# SYSCTRL_PADCONF_CORE register map
Vendor: Texas Instruments
Registers are 32-bit, access per field, reset 0x10F010F unless marked. A register's access mark holds for its fields unless they carry their own. Offsets are as the file gives them; [hi:lo] are bit positions; 'fields as' and 'values as' point back to an identical list.

## SYSCTRL_PADCONF_CORE (part 6 of 10)
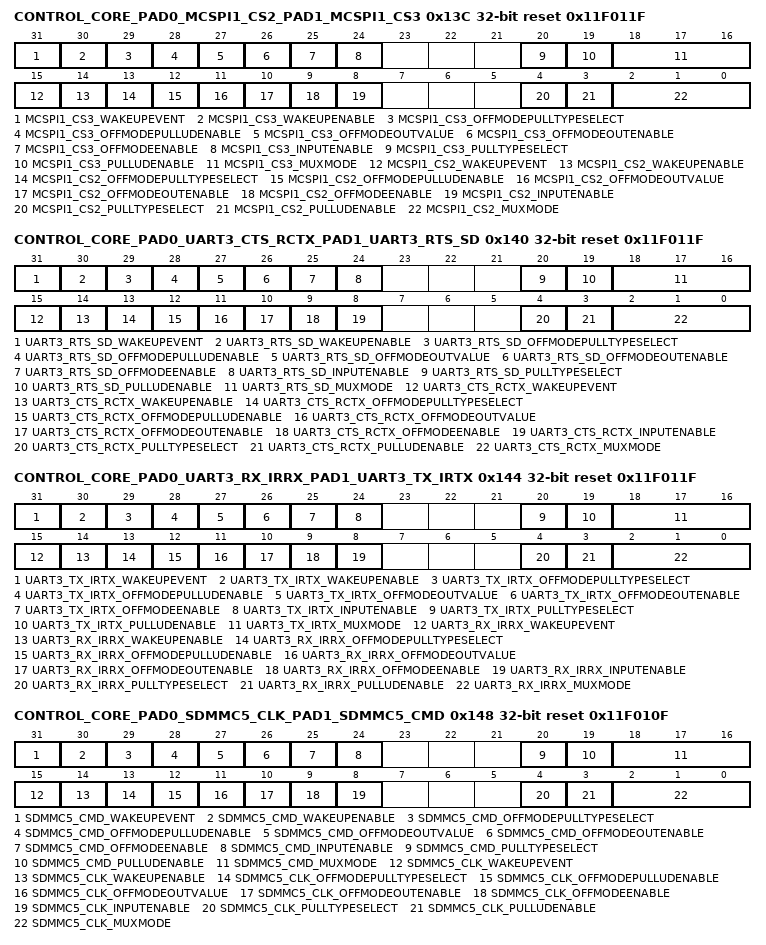
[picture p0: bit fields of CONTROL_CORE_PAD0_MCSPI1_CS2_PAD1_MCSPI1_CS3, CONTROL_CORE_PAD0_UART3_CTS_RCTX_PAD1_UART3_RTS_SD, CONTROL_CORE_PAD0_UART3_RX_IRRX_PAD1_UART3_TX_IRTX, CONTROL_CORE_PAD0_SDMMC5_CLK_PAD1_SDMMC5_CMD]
0x13C CONTROL_CORE_PAD0_MCSPI1_CS2_PAD1_MCSPI1_CS3 reset 0x11F011F — Register control for Pads mcspi1_cs2 and mcspi1_cs3 Access conditions. Read: unrestricted, Write: unrestricted
  [31] MCSPI1_CS3_WAKEUPEVENT ro — Pad_x wake-up event status latched in the IO
    0=MCSPI1_CS3_WAKEUPEVENT_0_r (No wake-up event occurred); 1=MCSPI1_CS3_WAKEUPEVENT_1_r (A wake-up event occurred)
  [30] MCSPI1_CS3_WAKEUPENABLE rw — Input pad wake-up enable (and OFF mode input enable value)
    0=wake-up detection is disabled; 1=wake-up detection is enabled
  [29] MCSPI1_CS3_OFFMODEPULLTYPESELECT rw — OffMode mode pullup/down selection for pad mcspi1_cs3
    0=Offmode pulldown selected; 1=Offmode pullup selected
  [28] MCSPI1_CS3_OFFMODEPULLUDENABLE rw — OffMode mode pullup/down enable for pad mcspi1_cs3
    0=Offmode pullup/down disabled; 1=Offmode pullup/down enabled
  [27] MCSPI1_CS3_OFFMODEOUTVALUE rw — OffMode mode output value for pad mcspi1_cs3
    0=Set value at 0; 1=Set value at 1
  [26] MCSPI1_CS3_OFFMODEOUTENABLE rw — OffMode mode output enable value for pad mcspi1_cs3. This is an active low signal
    0=Output enable; 1=Output disable
  [25] MCSPI1_CS3_OFFMODEENABLE rw — OffMode mode override control for pad mcspi1_cs3
    0=I/O state keeps its previous state when OFF mode is active; 1=I/O state is forced to OFF mode value when OFF mode is active
  [24] MCSPI1_CS3_INPUTENABLE rw — Input enable value for pad mcspi1_cs3
    0=Input buffer of I/O cell is disabled; 1=Input buffer of I/O cell is enabled
  [20] MCSPI1_CS3_PULLTYPESELECT rw — pullup/down selection for pad mcspi1_cs3
    0=pulldown selected; 1=pullup selected
  [19] MCSPI1_CS3_PULLUDENABLE rw — pullup/down enable for pad mcspi1_cs3
    0=pullup/down disabled; 1=pullup/down enabled
  [18:16] MCSPI1_CS3_MUXMODE rw — Functional multiplexing selection for pad mcspi1_cs3
    0=Select mcspi1_cs3; 1=Select uart1_rts; 2=Select slimbus2_data; 3=Select gpio_140; 7=Select safe_mode
  [15] MCSPI1_CS2_WAKEUPEVENT ro — Pad_x wake-up event status latched in the IO
    0=MCSPI1_CS2_WAKEUPEVENT_0_r (No wake-up event occurred); 1=MCSPI1_CS2_WAKEUPEVENT_1_r (A wake-up event occurred)
  [14] MCSPI1_CS2_WAKEUPENABLE rw — Input pad wake-up enable (and OFF mode input enable value)
    values as MCSPI1_CS3_WAKEUPENABLE
  [13] MCSPI1_CS2_OFFMODEPULLTYPESELECT rw — OffMode mode pullup/down selection for pad mcspi1_cs2
    0=Offmode pulldown selected; 1=Offmode pullup selected
  [12] MCSPI1_CS2_OFFMODEPULLUDENABLE rw — OffMode mode pullup/down enable for pad mcspi1_cs2
    values as MCSPI1_CS3_OFFMODEPULLUDENABLE
  [11] MCSPI1_CS2_OFFMODEOUTVALUE rw — OffMode mode output value for pad mcspi1_cs2
    0=Set value at 0; 1=Set value at 1
  [10] MCSPI1_CS2_OFFMODEOUTENABLE rw — OffMode mode output enable value for pad mcspi1_cs2. This is an active low signal
    0=Output enable; 1=Output disable
  [9] MCSPI1_CS2_OFFMODEENABLE rw — OffMode mode override control for pad mcspi1_cs2
    values as MCSPI1_CS3_OFFMODEENABLE
  [8] MCSPI1_CS2_INPUTENABLE rw — Input enable value for pad mcspi1_cs2
    values as MCSPI1_CS3_INPUTENABLE
  [4] MCSPI1_CS2_PULLTYPESELECT rw — pullup/down selection for pad mcspi1_cs2
    0=pulldown selected; 1=pullup selected
  [3] MCSPI1_CS2_PULLUDENABLE rw — pullup/down enable for pad mcspi1_cs2
    0=pullup/down disabled; 1=pullup/down enabled
  [2:0] MCSPI1_CS2_MUXMODE rw — Functional multiplexing selection for pad mcspi1_cs2
    0=Select mcspi1_cs2; 1=Select uart1_cts; 2=Select slimbus2_clock; 3=Select gpio_139; 7=Select safe_mode
0x140 CONTROL_CORE_PAD0_UART3_CTS_RCTX_PAD1_UART3_RTS_SD reset 0x11F011F — Register control for Pads uart3_cts_rctx and uart3_rts_sd Access conditions. Read: unrestricted, Write: unrestricted
  [31] UART3_RTS_SD_WAKEUPEVENT ro — Pad_x wake-up event status latched in the IO
    0=UART3_RTS_SD_WAKEUPEVENT_0_r (No wake-up event occurred); 1=UART3_RTS_SD_WAKEUPEVENT_1_r (A wake-up event occurred)
  [30] UART3_RTS_SD_WAKEUPENABLE rw — Input pad wake-up enable (and OFF mode input enable value)
    values as CONTROL_CORE_PAD0_MCSPI1_CS2_PAD1_MCSPI1_CS3.MCSPI1_CS3_WAKEUPENABLE
  [29] UART3_RTS_SD_OFFMODEPULLTYPESELECT rw — OffMode mode pullup/down selection for pad uart3_rts_sd
    0=Offmode pulldown selected; 1=Offmode pullup selected
  [28] UART3_RTS_SD_OFFMODEPULLUDENABLE rw — OffMode mode pullup/down enable for pad uart3_rts_sd
    values as CONTROL_CORE_PAD0_MCSPI1_CS2_PAD1_MCSPI1_CS3.MCSPI1_CS3_OFFMODEPULLUDENABLE
  [27] UART3_RTS_SD_OFFMODEOUTVALUE rw — OffMode mode output value for pad uart3_rts_sd
    0=Set value at 0; 1=Set value at 1
  [26] UART3_RTS_SD_OFFMODEOUTENABLE rw — OffMode mode output enable value for pad uart3_rts_sd. This is an active low signal
    0=Output enable; 1=Output disable
  [25] UART3_RTS_SD_OFFMODEENABLE rw — OffMode mode override control for pad uart3_rts_sd
    values as CONTROL_CORE_PAD0_MCSPI1_CS2_PAD1_MCSPI1_CS3.MCSPI1_CS3_OFFMODEENABLE
  [24] UART3_RTS_SD_INPUTENABLE rw — Input enable value for pad uart3_rts_sd
    values as CONTROL_CORE_PAD0_MCSPI1_CS2_PAD1_MCSPI1_CS3.MCSPI1_CS3_INPUTENABLE
  [20] UART3_RTS_SD_PULLTYPESELECT rw — pullup/down selection for pad uart3_rts_sd
    0=pulldown selected; 1=pullup selected
  [19] UART3_RTS_SD_PULLUDENABLE rw — pullup/down enable for pad uart3_rts_sd
    0=pullup/down disabled; 1=pullup/down enabled
  [18:16] UART3_RTS_SD_MUXMODE rw — Functional multiplexing selection for pad uart3_rts_sd
    0=Select uart3_rts_sd; 3=Select gpio_142; 7=Select safe_mode
  [15] UART3_CTS_RCTX_WAKEUPEVENT ro — Pad_x wake-up event status latched in the IO
    0=UART3_CTS_RCTX_WAKEUPEVENT_0_r (No wake-up event occurred); 1=UART3_CTS_RCTX_WAKEUPEVENT_1_r (A wake-up event occurred)
  [14] UART3_CTS_RCTX_WAKEUPENABLE rw — Input pad wake-up enable (and OFF mode input enable value)
    values as CONTROL_CORE_PAD0_MCSPI1_CS2_PAD1_MCSPI1_CS3.MCSPI1_CS3_WAKEUPENABLE
  [13] UART3_CTS_RCTX_OFFMODEPULLTYPESELECT rw — OffMode mode pullup/down selection for pad uart3_cts_rctx
    0=Offmode pulldown selected; 1=Offmode pullup selected
  [12] UART3_CTS_RCTX_OFFMODEPULLUDENABLE rw — OffMode mode pullup/down enable for pad uart3_cts_rctx
    values as CONTROL_CORE_PAD0_MCSPI1_CS2_PAD1_MCSPI1_CS3.MCSPI1_CS3_OFFMODEPULLUDENABLE
  [11] UART3_CTS_RCTX_OFFMODEOUTVALUE rw — OffMode mode output value for pad uart3_cts_rctx
    0=Set value at 0; 1=Set value at 1
  [10] UART3_CTS_RCTX_OFFMODEOUTENABLE rw — OffMode mode output enable value for pad uart3_cts_rctx. This is an active low signal
    0=Output enable; 1=Output disable
  [9] UART3_CTS_RCTX_OFFMODEENABLE rw — OffMode mode override control for pad uart3_cts_rctx
    values as CONTROL_CORE_PAD0_MCSPI1_CS2_PAD1_MCSPI1_CS3.MCSPI1_CS3_OFFMODEENABLE
  [8] UART3_CTS_RCTX_INPUTENABLE rw — Input enable value for pad uart3_cts_rctx
    values as CONTROL_CORE_PAD0_MCSPI1_CS2_PAD1_MCSPI1_CS3.MCSPI1_CS3_INPUTENABLE
  [4] UART3_CTS_RCTX_PULLTYPESELECT rw — pullup/down selection for pad uart3_cts_rctx
    0=pulldown selected; 1=pullup selected
  [3] UART3_CTS_RCTX_PULLUDENABLE rw — pullup/down enable for pad uart3_cts_rctx
    0=pullup/down disabled; 1=pullup/down enabled
  [2:0] UART3_CTS_RCTX_MUXMODE rw — Functional multiplexing selection for pad uart3_cts_rctx
    0=Select uart3_cts_rctx; 1=Select uart1_tx; 3=Select gpio_141; 7=Select safe_mode
0x144 CONTROL_CORE_PAD0_UART3_RX_IRRX_PAD1_UART3_TX_IRTX reset 0x11F011F — Register control for Pads uart3_rx_irrx and uart3_tx_irtx Access conditions. Read: unrestricted, Write: unrestricted
  [31] UART3_TX_IRTX_WAKEUPEVENT ro — Pad_x wake-up event status latched in the IO
    0=UART3_TX_IRTX_WAKEUPEVENT_0_r (No wake-up event occurred); 1=UART3_TX_IRTX_WAKEUPEVENT_1_r (A wake-up event occurred)
  [30] UART3_TX_IRTX_WAKEUPENABLE rw — Input pad wake-up enable (and OFF mode input enable value)
    values as CONTROL_CORE_PAD0_MCSPI1_CS2_PAD1_MCSPI1_CS3.MCSPI1_CS3_WAKEUPENABLE
  [29] UART3_TX_IRTX_OFFMODEPULLTYPESELECT rw — OffMode mode pullup/down selection for pad uart3_tx_irtx
    0=Offmode pulldown selected; 1=Offmode pullup selected
  [28] UART3_TX_IRTX_OFFMODEPULLUDENABLE rw — OffMode mode pullup/down enable for pad uart3_tx_irtx
    values as CONTROL_CORE_PAD0_MCSPI1_CS2_PAD1_MCSPI1_CS3.MCSPI1_CS3_OFFMODEPULLUDENABLE
  [27] UART3_TX_IRTX_OFFMODEOUTVALUE rw — OffMode mode output value for pad uart3_tx_irtx
    0=Set value at 0; 1=Set value at 1
  [26] UART3_TX_IRTX_OFFMODEOUTENABLE rw — OffMode mode output enable value for pad uart3_tx_irtx. This is an active low signal
    0=Output enable; 1=Output disable
  [25] UART3_TX_IRTX_OFFMODEENABLE rw — OffMode mode override control for pad uart3_tx_irtx
    values as CONTROL_CORE_PAD0_MCSPI1_CS2_PAD1_MCSPI1_CS3.MCSPI1_CS3_OFFMODEENABLE
  [24] UART3_TX_IRTX_INPUTENABLE rw — Input enable value for pad uart3_tx_irtx
    values as CONTROL_CORE_PAD0_MCSPI1_CS2_PAD1_MCSPI1_CS3.MCSPI1_CS3_INPUTENABLE
  [20] UART3_TX_IRTX_PULLTYPESELECT rw — pullup/down selection for pad uart3_tx_irtx
    0=pulldown selected; 1=pullup selected
  [19] UART3_TX_IRTX_PULLUDENABLE rw — pullup/down enable for pad uart3_tx_irtx
    0=pullup/down disabled; 1=pullup/down enabled
  [18:16] UART3_TX_IRTX_MUXMODE rw — Functional multiplexing selection for pad uart3_tx_irtx
    0=Select uart3_tx_irtx; 1=Select dmtimer9_pwm_evt; 3=Select gpio_144; 7=Select safe_mode
  [15] UART3_RX_IRRX_WAKEUPEVENT ro — Pad_x wake-up event status latched in the IO
    0=UART3_RX_IRRX_WAKEUPEVENT_0_r (No wake-up event occurred); 1=UART3_RX_IRRX_WAKEUPEVENT_1_r (A wake-up event occurred)
  [14] UART3_RX_IRRX_WAKEUPENABLE rw — Input pad wake-up enable (and OFF mode input enable value)
    values as CONTROL_CORE_PAD0_MCSPI1_CS2_PAD1_MCSPI1_CS3.MCSPI1_CS3_WAKEUPENABLE
  [13] UART3_RX_IRRX_OFFMODEPULLTYPESELECT rw — OffMode mode pullup/down selection for pad uart3_rx_irrx
    0=Offmode pulldown selected; 1=Offmode pullup selected
  [12] UART3_RX_IRRX_OFFMODEPULLUDENABLE rw — OffMode mode pullup/down enable for pad uart3_rx_irrx
    values as CONTROL_CORE_PAD0_MCSPI1_CS2_PAD1_MCSPI1_CS3.MCSPI1_CS3_OFFMODEPULLUDENABLE
  [11] UART3_RX_IRRX_OFFMODEOUTVALUE rw — OffMode mode output value for pad uart3_rx_irrx
    0=Set value at 0; 1=Set value at 1
  [10] UART3_RX_IRRX_OFFMODEOUTENABLE rw — OffMode mode output enable value for pad uart3_rx_irrx. This is an active low signal
    0=Output enable; 1=Output disable
  [9] UART3_RX_IRRX_OFFMODEENABLE rw — OffMode mode override control for pad uart3_rx_irrx
    values as CONTROL_CORE_PAD0_MCSPI1_CS2_PAD1_MCSPI1_CS3.MCSPI1_CS3_OFFMODEENABLE
  [8] UART3_RX_IRRX_INPUTENABLE rw — Input enable value for pad uart3_rx_irrx
    values as CONTROL_CORE_PAD0_MCSPI1_CS2_PAD1_MCSPI1_CS3.MCSPI1_CS3_INPUTENABLE
  [4] UART3_RX_IRRX_PULLTYPESELECT rw — pullup/down selection for pad uart3_rx_irrx
    0=pulldown selected; 1=pullup selected
  [3] UART3_RX_IRRX_PULLUDENABLE rw — pullup/down enable for pad uart3_rx_irrx
    0=pullup/down disabled; 1=pullup/down enabled
  [2:0] UART3_RX_IRRX_MUXMODE rw — Functional multiplexing selection for pad uart3_rx_irrx
    0=Select uart3_rx_irrx; 1=Select dmtimer8_pwm_evt; 3=Select gpio_143; 7=Select safe_mode
0x148 CONTROL_CORE_PAD0_SDMMC5_CLK_PAD1_SDMMC5_CMD reset 0x11F010F — Register control for Pads sdmmc5_clk and sdmmc5_cmd Access conditions. Read: unrestricted, Write: unrestricted
  [31] SDMMC5_CMD_WAKEUPEVENT ro — Pad_x wake-up event status latched in the IO
    0=SDMMC5_CMD_WAKEUPEVENT_0_r (No wake-up event occurred); 1=SDMMC5_CMD_WAKEUPEVENT_1_r (A wake-up event occurred)
  [30] SDMMC5_CMD_WAKEUPENABLE rw — Input pad wake-up enable (and OFF mode input enable value)
    values as CONTROL_CORE_PAD0_MCSPI1_CS2_PAD1_MCSPI1_CS3.MCSPI1_CS3_WAKEUPENABLE
  [29] SDMMC5_CMD_OFFMODEPULLTYPESELECT rw — OffMode mode pullup/down selection for pad sdmmc5_cmd
    0=Offmode pulldown selected; 1=Offmode pullup selected
  [28] SDMMC5_CMD_OFFMODEPULLUDENABLE rw — OffMode mode pullup/down enable for pad sdmmc5_cmd
    values as CONTROL_CORE_PAD0_MCSPI1_CS2_PAD1_MCSPI1_CS3.MCSPI1_CS3_OFFMODEPULLUDENABLE
  [27] SDMMC5_CMD_OFFMODEOUTVALUE rw — OffMode mode output value for pad sdmmc5_cmd
    0=Set value at 0; 1=Set value at 1
  [26] SDMMC5_CMD_OFFMODEOUTENABLE rw — OffMode mode output enable value for pad sdmmc5_cmd. This is an active low signal
    0=Output enable; 1=Output disable
  [25] SDMMC5_CMD_OFFMODEENABLE rw — OffMode mode override control for pad sdmmc5_cmd
    values as CONTROL_CORE_PAD0_MCSPI1_CS2_PAD1_MCSPI1_CS3.MCSPI1_CS3_OFFMODEENABLE
  [24] SDMMC5_CMD_INPUTENABLE rw — Input enable value for pad sdmmc5_cmd
    values as CONTROL_CORE_PAD0_MCSPI1_CS2_PAD1_MCSPI1_CS3.MCSPI1_CS3_INPUTENABLE
  [20] SDMMC5_CMD_PULLTYPESELECT rw — pullup/down selection for pad sdmmc5_cmd
    0=pulldown selected; 1=pullup selected
  [19] SDMMC5_CMD_PULLUDENABLE rw — pullup/down enable for pad sdmmc5_cmd
    0=pullup/down disabled; 1=pullup/down enabled
  [18:16] SDMMC5_CMD_MUXMODE rw — Functional multiplexing selection for pad sdmmc5_cmd
    0=Select sdmmc5_cmd; 1=Select mcspi2_simo; 2=Select usbc1_icusb_dm; 3=Select gpio_146; 5=Select sdmmc2_cmd; 7=Select safe_mode
  [15] SDMMC5_CLK_WAKEUPEVENT ro — Pad_x wake-up event status latched in the IO
    0=SDMMC5_CLK_WAKEUPEVENT_0_r (No wake-up event occurred); 1=SDMMC5_CLK_WAKEUPEVENT_1_r (A wake-up event occurred)
  [14] SDMMC5_CLK_WAKEUPENABLE rw — Input pad wake-up enable (and OFF mode input enable value)
    values as CONTROL_CORE_PAD0_MCSPI1_CS2_PAD1_MCSPI1_CS3.MCSPI1_CS3_WAKEUPENABLE
  [13] SDMMC5_CLK_OFFMODEPULLTYPESELECT rw — OffMode mode pullup/down selection for pad sdmmc5_clk
    0=Offmode pulldown selected; 1=Offmode pullup selected
  [12] SDMMC5_CLK_OFFMODEPULLUDENABLE rw — OffMode mode pullup/down enable for pad sdmmc5_clk
    values as CONTROL_CORE_PAD0_MCSPI1_CS2_PAD1_MCSPI1_CS3.MCSPI1_CS3_OFFMODEPULLUDENABLE
  [11] SDMMC5_CLK_OFFMODEOUTVALUE rw — OffMode mode output value for pad sdmmc5_clk
    0=Set value at 0; 1=Set value at 1
  [10] SDMMC5_CLK_OFFMODEOUTENABLE rw — OffMode mode output enable value for pad sdmmc5_clk. This is an active low signal
    0=Output enable; 1=Output disable
  [9] SDMMC5_CLK_OFFMODEENABLE rw — OffMode mode override control for pad sdmmc5_clk
    values as CONTROL_CORE_PAD0_MCSPI1_CS2_PAD1_MCSPI1_CS3.MCSPI1_CS3_OFFMODEENABLE
  [8] SDMMC5_CLK_INPUTENABLE rw — Input enable value for pad sdmmc5_clk
    values as CONTROL_CORE_PAD0_MCSPI1_CS2_PAD1_MCSPI1_CS3.MCSPI1_CS3_INPUTENABLE
  [4] SDMMC5_CLK_PULLTYPESELECT rw — pullup/down selection for pad sdmmc5_clk
    0=pulldown selected; 1=pullup selected
  [3] SDMMC5_CLK_PULLUDENABLE rw — pullup/down enable for pad sdmmc5_clk
    0=pullup/down disabled; 1=pullup/down enabled
  [2:0] SDMMC5_CLK_MUXMODE rw — Functional multiplexing selection for pad sdmmc5_clk
    0=Select sdmmc5_clk; 1=Select mcspi2_clk; 2=Select usbc1_icusb_dp; 3=Select gpio_145; 5=Select sdmmc2_clk; 7=Select safe_mode
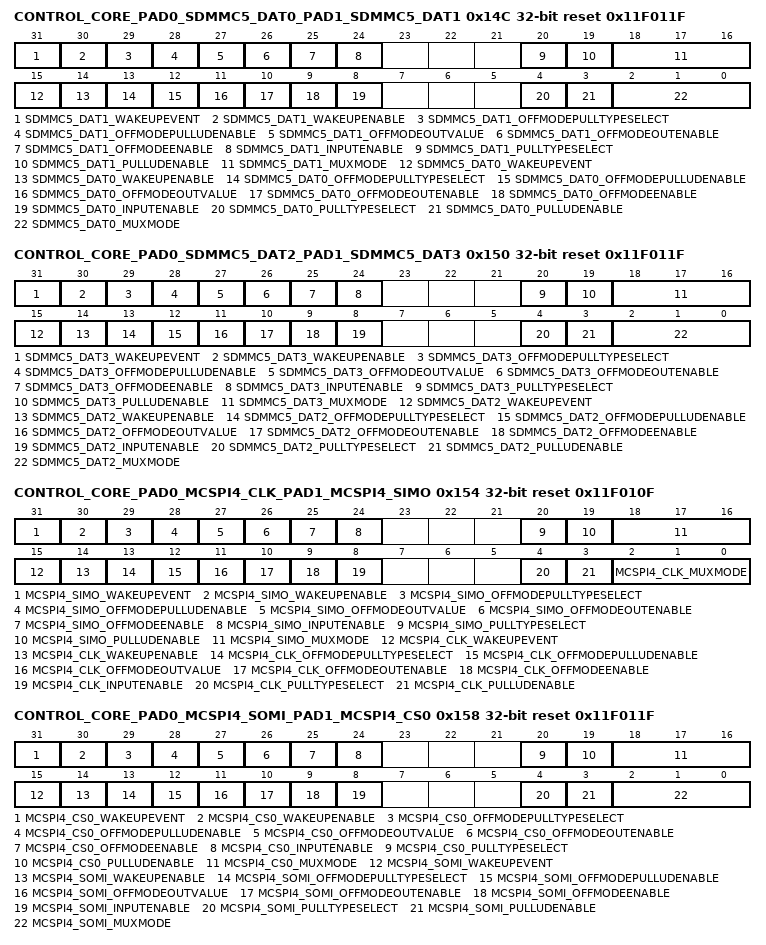
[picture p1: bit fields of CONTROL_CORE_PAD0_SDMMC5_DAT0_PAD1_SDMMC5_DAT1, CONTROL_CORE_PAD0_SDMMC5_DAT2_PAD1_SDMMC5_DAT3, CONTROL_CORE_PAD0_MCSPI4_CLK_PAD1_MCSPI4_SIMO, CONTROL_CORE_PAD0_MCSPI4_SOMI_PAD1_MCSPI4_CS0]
0x14C CONTROL_CORE_PAD0_SDMMC5_DAT0_PAD1_SDMMC5_DAT1 reset 0x11F011F — Register control for Pads sdmmc5_dat0 and sdmmc5_dat1 Access conditions. Read: unrestricted, Write: unrestricted
  [31] SDMMC5_DAT1_WAKEUPEVENT ro — Pad_x wake-up event status latched in the IO
    0=SDMMC5_DAT1_WAKEUPEVENT_0_r (No wake-up event occurred); 1=SDMMC5_DAT1_WAKEUPEVENT_1_r (A wake-up event occurred)
  [30] SDMMC5_DAT1_WAKEUPENABLE rw — Input pad wake-up enable (and OFF mode input enable value)
    values as CONTROL_CORE_PAD0_MCSPI1_CS2_PAD1_MCSPI1_CS3.MCSPI1_CS3_WAKEUPENABLE
  [29] SDMMC5_DAT1_OFFMODEPULLTYPESELECT rw — OffMode mode pullup/down selection for pad sdmmc5_dat1
    0=Offmode pulldown selected; 1=Offmode pullup selected
  [28] SDMMC5_DAT1_OFFMODEPULLUDENABLE rw — OffMode mode pullup/down enable for pad sdmmc5_dat1
    values as CONTROL_CORE_PAD0_MCSPI1_CS2_PAD1_MCSPI1_CS3.MCSPI1_CS3_OFFMODEPULLUDENABLE
  [27] SDMMC5_DAT1_OFFMODEOUTVALUE rw — OffMode mode output value for pad sdmmc5_dat1
    0=Set value at 0; 1=Set value at 1
  [26] SDMMC5_DAT1_OFFMODEOUTENABLE rw — OffMode mode output enable value for pad sdmmc5_dat1. This is an active low signal
    0=Output enable; 1=Output disable
  [25] SDMMC5_DAT1_OFFMODEENABLE rw — OffMode mode override control for pad sdmmc5_dat1
    values as CONTROL_CORE_PAD0_MCSPI1_CS2_PAD1_MCSPI1_CS3.MCSPI1_CS3_OFFMODEENABLE
  [24] SDMMC5_DAT1_INPUTENABLE rw — Input enable value for pad sdmmc5_dat1
    values as CONTROL_CORE_PAD0_MCSPI1_CS2_PAD1_MCSPI1_CS3.MCSPI1_CS3_INPUTENABLE
  [20] SDMMC5_DAT1_PULLTYPESELECT rw — pullup/down selection for pad sdmmc5_dat1
    0=pulldown selected; 1=pullup selected
  [19] SDMMC5_DAT1_PULLUDENABLE rw — pullup/down enable for pad sdmmc5_dat1
    0=pullup/down disabled; 1=pullup/down enabled
  [18:16] SDMMC5_DAT1_MUXMODE rw — Functional multiplexing selection for pad sdmmc5_dat1
    0=Select sdmmc5_dat1; 2=Select usbc1_icusb_txen; 3=Select gpio_148; 5=Select sdmmc2_dat1; 7=Select safe_mode
  [15] SDMMC5_DAT0_WAKEUPEVENT ro — Pad_x wake-up event status latched in the IO
    0=SDMMC5_DAT0_WAKEUPEVENT_0_r (No wake-up event occurred); 1=SDMMC5_DAT0_WAKEUPEVENT_1_r (A wake-up event occurred)
  [14] SDMMC5_DAT0_WAKEUPENABLE rw — Input pad wake-up enable (and OFF mode input enable value)
    values as CONTROL_CORE_PAD0_MCSPI1_CS2_PAD1_MCSPI1_CS3.MCSPI1_CS3_WAKEUPENABLE
  [13] SDMMC5_DAT0_OFFMODEPULLTYPESELECT rw — OffMode mode pullup/down selection for pad sdmmc5_dat0
    0=Offmode pulldown selected; 1=Offmode pullup selected
  [12] SDMMC5_DAT0_OFFMODEPULLUDENABLE rw — OffMode mode pullup/down enable for pad sdmmc5_dat0
    values as CONTROL_CORE_PAD0_MCSPI1_CS2_PAD1_MCSPI1_CS3.MCSPI1_CS3_OFFMODEPULLUDENABLE
  [11] SDMMC5_DAT0_OFFMODEOUTVALUE rw — OffMode mode output value for pad sdmmc5_dat0
    0=Set value at 0; 1=Set value at 1
  [10] SDMMC5_DAT0_OFFMODEOUTENABLE rw — OffMode mode output enable value for pad sdmmc5_dat0. This is an active low signal
    0=Output enable; 1=Output disable
  [9] SDMMC5_DAT0_OFFMODEENABLE rw — OffMode mode override control for pad sdmmc5_dat0
    values as CONTROL_CORE_PAD0_MCSPI1_CS2_PAD1_MCSPI1_CS3.MCSPI1_CS3_OFFMODEENABLE
  [8] SDMMC5_DAT0_INPUTENABLE rw — Input enable value for pad sdmmc5_dat0
    values as CONTROL_CORE_PAD0_MCSPI1_CS2_PAD1_MCSPI1_CS3.MCSPI1_CS3_INPUTENABLE
  [4] SDMMC5_DAT0_PULLTYPESELECT rw — pullup/down selection for pad sdmmc5_dat0
    0=pulldown selected; 1=pullup selected
  [3] SDMMC5_DAT0_PULLUDENABLE rw — pullup/down enable for pad sdmmc5_dat0
    0=pullup/down disabled; 1=pullup/down enabled
  [2:0] SDMMC5_DAT0_MUXMODE rw — Functional multiplexing selection for pad sdmmc5_dat0
    0=Select sdmmc5_dat0; 1=Select mcspi2_somi; 2=Select usbc1_icusb_rcv; 3=Select gpio_147; 5=sdmmc2_dat0; 7=Select safe_mode
0x150 CONTROL_CORE_PAD0_SDMMC5_DAT2_PAD1_SDMMC5_DAT3 reset 0x11F011F — Register control for Pads sdmmc5_dat2 and sdmmc5_dat3 Access conditions. Read: unrestricted, Write: unrestricted
  [31] SDMMC5_DAT3_WAKEUPEVENT ro — Pad_x wake-up event status latched in the IO
    0=SDMMC5_DAT3_WAKEUPEVENT_0_r (No wake-up event occurred); 1=SDMMC5_DAT3_WAKEUPEVENT_1_r (A wake-up event occurred)
  [30] SDMMC5_DAT3_WAKEUPENABLE rw — Input pad wake-up enable (and OFF mode input enable value)
    values as CONTROL_CORE_PAD0_MCSPI1_CS2_PAD1_MCSPI1_CS3.MCSPI1_CS3_WAKEUPENABLE
  [29] SDMMC5_DAT3_OFFMODEPULLTYPESELECT rw — OffMode mode pullup/down selection for pad sdmmc5_dat3
    0=Offmode pulldown selected; 1=Offmode pullup selected
  [28] SDMMC5_DAT3_OFFMODEPULLUDENABLE rw — OffMode mode pullup/down enable for pad sdmmc5_dat3
    values as CONTROL_CORE_PAD0_MCSPI1_CS2_PAD1_MCSPI1_CS3.MCSPI1_CS3_OFFMODEPULLUDENABLE
  [27] SDMMC5_DAT3_OFFMODEOUTVALUE rw — OffMode mode output value for pad sdmmc5_dat3
    0=Set value at 0; 1=Set value at 1
  [26] SDMMC5_DAT3_OFFMODEOUTENABLE rw — OffMode mode output enable value for pad sdmmc5_dat3. This is an active low signal
    0=Output enable; 1=Output disable
  [25] SDMMC5_DAT3_OFFMODEENABLE rw — OffMode mode override control for pad sdmmc5_dat3
    values as CONTROL_CORE_PAD0_MCSPI1_CS2_PAD1_MCSPI1_CS3.MCSPI1_CS3_OFFMODEENABLE
  [24] SDMMC5_DAT3_INPUTENABLE rw — Input enable value for pad sdmmc5_dat3
    values as CONTROL_CORE_PAD0_MCSPI1_CS2_PAD1_MCSPI1_CS3.MCSPI1_CS3_INPUTENABLE
  [20] SDMMC5_DAT3_PULLTYPESELECT rw — pullup/down selection for pad sdmmc5_dat3
    0=pulldown selected; 1=pullup selected
  [19] SDMMC5_DAT3_PULLUDENABLE rw — pullup/down enable for pad sdmmc5_dat3
    0=pullup/down disabled; 1=pullup/down enabled
  [18:16] SDMMC5_DAT3_MUXMODE rw — Functional multiplexing selection for pad sdmmc5_dat3
    0=Select sdmmc5_dat3; 1=Select mcspi2_cs0; 3=Select gpio_150; 5=Select sdmmc2_dat3; 7=Select safe_mode
  [15] SDMMC5_DAT2_WAKEUPEVENT ro — Pad_x wake-up event status latched in the IO
    0=SDMMC5_DAT2_WAKEUPEVENT_0_r (No wake-up event occurred); 1=SDMMC5_DAT2_WAKEUPEVENT_1_r (A wake-up event occurred)
  [14] SDMMC5_DAT2_WAKEUPENABLE rw — Input pad wake-up enable (and OFF mode input enable value)
    values as CONTROL_CORE_PAD0_MCSPI1_CS2_PAD1_MCSPI1_CS3.MCSPI1_CS3_WAKEUPENABLE
  [13] SDMMC5_DAT2_OFFMODEPULLTYPESELECT rw — OffMode mode pullup/down selection for pad sdmmc5_dat2
    0=Offmode pulldown selected; 1=Offmode pullup selected
  [12] SDMMC5_DAT2_OFFMODEPULLUDENABLE rw — OffMode mode pullup/down enable for pad sdmmc5_dat2
    values as CONTROL_CORE_PAD0_MCSPI1_CS2_PAD1_MCSPI1_CS3.MCSPI1_CS3_OFFMODEPULLUDENABLE
  [11] SDMMC5_DAT2_OFFMODEOUTVALUE rw — OffMode mode output value for pad sdmmc5_dat2
    0=Set value at 0; 1=Set value at 1
  [10] SDMMC5_DAT2_OFFMODEOUTENABLE rw — OffMode mode output enable value for pad sdmmc5_dat2. This is an active low signal
    0=Output enable; 1=Output disable
  [9] SDMMC5_DAT2_OFFMODEENABLE rw — OffMode mode override control for pad sdmmc5_dat2
    values as CONTROL_CORE_PAD0_MCSPI1_CS2_PAD1_MCSPI1_CS3.MCSPI1_CS3_OFFMODEENABLE
  [8] SDMMC5_DAT2_INPUTENABLE rw — Input enable value for pad sdmmc5_dat2
    values as CONTROL_CORE_PAD0_MCSPI1_CS2_PAD1_MCSPI1_CS3.MCSPI1_CS3_INPUTENABLE
  [4] SDMMC5_DAT2_PULLTYPESELECT rw — pullup/down selection for pad sdmmc5_dat2
    0=pulldown selected; 1=pullup selected
  [3] SDMMC5_DAT2_PULLUDENABLE rw — pullup/down enable for pad sdmmc5_dat2
    0=pullup/down disabled; 1=pullup/down enabled
  [2:0] SDMMC5_DAT2_MUXMODE rw — Functional multiplexing selection for pad sdmmc5_dat2
    0=Select sdmmc5_dat2; 1=Select mcspi2_cs1; 3=Select gpio_149; 5=Select sdmmc2_dat2; 7=Select safe_mode
0x154 CONTROL_CORE_PAD0_MCSPI4_CLK_PAD1_MCSPI4_SIMO reset 0x11F010F — Register control for Pads mcspi4_clk and mcspi4_simo Access conditions. Read: unrestricted, Write: unrestricted
  [31] MCSPI4_SIMO_WAKEUPEVENT ro — Pad_x wake-up event status latched in the IO
    0=MCSPI4_SIMO_WAKEUPEVENT_0_r (No wake-up event occurred); 1=MCSPI4_SIMO_WAKEUPEVENT_1_r (A wake-up event occurred)
  [30] MCSPI4_SIMO_WAKEUPENABLE rw — Input pad wake-up enable (and OFF mode input enable value)
    values as CONTROL_CORE_PAD0_MCSPI1_CS2_PAD1_MCSPI1_CS3.MCSPI1_CS3_WAKEUPENABLE
  [29] MCSPI4_SIMO_OFFMODEPULLTYPESELECT rw — OffMode mode pullup/down selection for pad mcspi4_simo
    0=Offmode pulldown selected; 1=Offmode pullup selected
  [28] MCSPI4_SIMO_OFFMODEPULLUDENABLE rw — OffMode mode pullup/down enable for pad mcspi4_simo
    values as CONTROL_CORE_PAD0_MCSPI1_CS2_PAD1_MCSPI1_CS3.MCSPI1_CS3_OFFMODEPULLUDENABLE
  [27] MCSPI4_SIMO_OFFMODEOUTVALUE rw — OffMode mode output value for pad mcspi4_simo
    0=Set value at 0; 1=Set value at 1
  [26] MCSPI4_SIMO_OFFMODEOUTENABLE rw — OffMode mode output enable value for pad mcspi4_simo. This is an active low signal
    0=Output enable; 1=Output disable
  [25] MCSPI4_SIMO_OFFMODEENABLE rw — OffMode mode override control for pad mcspi4_simo
    values as CONTROL_CORE_PAD0_MCSPI1_CS2_PAD1_MCSPI1_CS3.MCSPI1_CS3_OFFMODEENABLE
  [24] MCSPI4_SIMO_INPUTENABLE rw — Input enable value for pad mcspi4_simo
    values as CONTROL_CORE_PAD0_MCSPI1_CS2_PAD1_MCSPI1_CS3.MCSPI1_CS3_INPUTENABLE
  [20] MCSPI4_SIMO_PULLTYPESELECT rw — pullup/down selection for pad mcspi4_simo
    0=pulldown selected; 1=pullup selected
  [19] MCSPI4_SIMO_PULLUDENABLE rw — pullup/down enable for pad mcspi4_simo
    0=pullup/down disabled; 1=pullup/down enabled
  [18:16] MCSPI4_SIMO_MUXMODE rw — Functional multiplexing selection for pad mcspi4_simo
    0=Select mcspi4_simo; 1=Select sdmmc4_cmd; 2=Select kpd_col7; 3=Select gpio_152; 7=Select safe_mode
  [15] MCSPI4_CLK_WAKEUPEVENT ro — Pad_x wake-up event status latched in the IO
    0=MCSPI4_CLK_WAKEUPEVENT_0_r (No wake-up event occurred); 1=MCSPI4_CLK_WAKEUPEVENT_1_r (A wake-up event occurred)
  [14] MCSPI4_CLK_WAKEUPENABLE rw — Input pad wake-up enable (and OFF mode input enable value)
    values as CONTROL_CORE_PAD0_MCSPI1_CS2_PAD1_MCSPI1_CS3.MCSPI1_CS3_WAKEUPENABLE
  [13] MCSPI4_CLK_OFFMODEPULLTYPESELECT rw — OffMode mode pullup/down selection for pad mcspi4_clk
    0=Offmode pulldown selected; 1=Offmode pullup selected
  [12] MCSPI4_CLK_OFFMODEPULLUDENABLE rw — OffMode mode pullup/down enable for pad mcspi4_clk
    values as CONTROL_CORE_PAD0_MCSPI1_CS2_PAD1_MCSPI1_CS3.MCSPI1_CS3_OFFMODEPULLUDENABLE
  [11] MCSPI4_CLK_OFFMODEOUTVALUE rw — OffMode mode output value for pad mcspi4_clk
    0=Set value at 0; 1=Set value at 1
  [10] MCSPI4_CLK_OFFMODEOUTENABLE rw — OffMode mode output enable value for pad mcspi4_clk. This is an active low signal
    0=Output enable; 1=Output disable
  [9] MCSPI4_CLK_OFFMODEENABLE rw — OffMode mode override control for pad mcspi4_clk
    values as CONTROL_CORE_PAD0_MCSPI1_CS2_PAD1_MCSPI1_CS3.MCSPI1_CS3_OFFMODEENABLE
  [8] MCSPI4_CLK_INPUTENABLE rw — Input enable value for pad mcspi4_clk
    values as CONTROL_CORE_PAD0_MCSPI1_CS2_PAD1_MCSPI1_CS3.MCSPI1_CS3_INPUTENABLE
  [4] MCSPI4_CLK_PULLTYPESELECT rw — pullup/down selection for pad mcspi4_clk
    0=pulldown selected; 1=pullup selected
  [3] MCSPI4_CLK_PULLUDENABLE rw — pullup/down enable for pad mcspi4_clk
    0=pullup/down disabled; 1=pullup/down enabled
  [2:0] MCSPI4_CLK_MUXMODE rw — Functional multiplexing selection for pad mcspi4_clk
    0=Select mcspi4_clk; 1=Select sdmmc4_clk; 2=Select kpd_col6; 3=Select gpio_151; 7=Select safe_mode
0x158 CONTROL_CORE_PAD0_MCSPI4_SOMI_PAD1_MCSPI4_CS0 reset 0x11F011F — Register control for Pads mcspi4_somi and mcspi4_cs0 Access conditions. Read: unrestricted, Write: unrestricted
  [31] MCSPI4_CS0_WAKEUPEVENT ro — Pad_x wake-up event status latched in the IO
    0=MCSPI4_CS0_WAKEUPEVENT_0_r (No wake-up event occurred); 1=MCSPI4_CS0_WAKEUPEVENT_1_r (A wake-up event occurred)
  [30] MCSPI4_CS0_WAKEUPENABLE rw — Input pad wake-up enable (and OFF mode input enable value)
    values as CONTROL_CORE_PAD0_MCSPI1_CS2_PAD1_MCSPI1_CS3.MCSPI1_CS3_WAKEUPENABLE
  [29] MCSPI4_CS0_OFFMODEPULLTYPESELECT rw — OffMode mode pullup/down selection for pad mcspi4_cs0
    0=Offmode pulldown selected; 1=Offmode pullup selected
  [28] MCSPI4_CS0_OFFMODEPULLUDENABLE rw — OffMode mode pullup/down enable for pad mcspi4_cs0
    values as CONTROL_CORE_PAD0_MCSPI1_CS2_PAD1_MCSPI1_CS3.MCSPI1_CS3_OFFMODEPULLUDENABLE
  [27] MCSPI4_CS0_OFFMODEOUTVALUE rw — OffMode mode output value for pad mcspi4_cs0
    0=Set value at 0; 1=Set value at 1
  [26] MCSPI4_CS0_OFFMODEOUTENABLE rw — OffMode mode output enable value for pad mcspi4_cs0. This is an active low signal
    0=Output enable; 1=Output disable
  [25] MCSPI4_CS0_OFFMODEENABLE rw — OffMode mode override control for pad mcspi4_cs0
    values as CONTROL_CORE_PAD0_MCSPI1_CS2_PAD1_MCSPI1_CS3.MCSPI1_CS3_OFFMODEENABLE
  [24] MCSPI4_CS0_INPUTENABLE rw — Input enable value for pad mcspi4_cs0
    values as CONTROL_CORE_PAD0_MCSPI1_CS2_PAD1_MCSPI1_CS3.MCSPI1_CS3_INPUTENABLE
  [20] MCSPI4_CS0_PULLTYPESELECT rw — pullup/down selection for pad mcspi4_cs0
    0=pulldown selected; 1=pullup selected
  [19] MCSPI4_CS0_PULLUDENABLE rw — pullup/down enable for pad mcspi4_cs0
    0=pullup/down disabled; 1=pullup/down enabled
  [18:16] MCSPI4_CS0_MUXMODE rw — Functional multiplexing selection for pad mcspi4_cs0
    0=Select mcspi4_cs0; 1=Select sdmmc4_dat3; 2=Select kpd_row7; 3=Select gpio_154; 7=Select safe_mode
  [15] MCSPI4_SOMI_WAKEUPEVENT ro — Pad_x wake-up event status latched in the IO
    0=MCSPI4_SOMI_WAKEUPEVENT_0_r (No wake-up event occurred); 1=MCSPI4_SOMI_WAKEUPEVENT_1_r (A wake-up event occurred)
  [14] MCSPI4_SOMI_WAKEUPENABLE rw — Input pad wake-up enable (and OFF mode input enable value)
    values as CONTROL_CORE_PAD0_MCSPI1_CS2_PAD1_MCSPI1_CS3.MCSPI1_CS3_WAKEUPENABLE
  [13] MCSPI4_SOMI_OFFMODEPULLTYPESELECT rw — OffMode mode pullup/down selection for pad mcspi4_somi
    0=Offmode pulldown selected; 1=Offmode pullup selected
  [12] MCSPI4_SOMI_OFFMODEPULLUDENABLE rw — OffMode mode pullup/down enable for pad mcspi4_somi
    values as CONTROL_CORE_PAD0_MCSPI1_CS2_PAD1_MCSPI1_CS3.MCSPI1_CS3_OFFMODEPULLUDENABLE
  [11] MCSPI4_SOMI_OFFMODEOUTVALUE rw — OffMode mode output value for pad mcspi4_somi
    0=Set value at 0; 1=Set value at 1
  [10] MCSPI4_SOMI_OFFMODEOUTENABLE rw — OffMode mode output enable value for pad mcspi4_somi. This is an active low signal
    0=Output enable; 1=Output disable
  [9] MCSPI4_SOMI_OFFMODEENABLE rw — OffMode mode override control for pad mcspi4_somi
    values as CONTROL_CORE_PAD0_MCSPI1_CS2_PAD1_MCSPI1_CS3.MCSPI1_CS3_OFFMODEENABLE
  [8] MCSPI4_SOMI_INPUTENABLE rw — Input enable value for pad mcspi4_somi
    values as CONTROL_CORE_PAD0_MCSPI1_CS2_PAD1_MCSPI1_CS3.MCSPI1_CS3_INPUTENABLE
  [4] MCSPI4_SOMI_PULLTYPESELECT rw — pullup/down selection for pad mcspi4_somi
    0=pulldown selected; 1=pullup selected
  [3] MCSPI4_SOMI_PULLUDENABLE rw — pullup/down enable for pad mcspi4_somi
    0=pullup/down disabled; 1=pullup/down enabled
  [2:0] MCSPI4_SOMI_MUXMODE rw — Functional multiplexing selection for pad mcspi4_somi
    0=Select mcspi4_somi; 1=Select sdmmc4_dat0; 2=Select kpd_row6; 3=Select gpio_153; 7=Select safe_mode
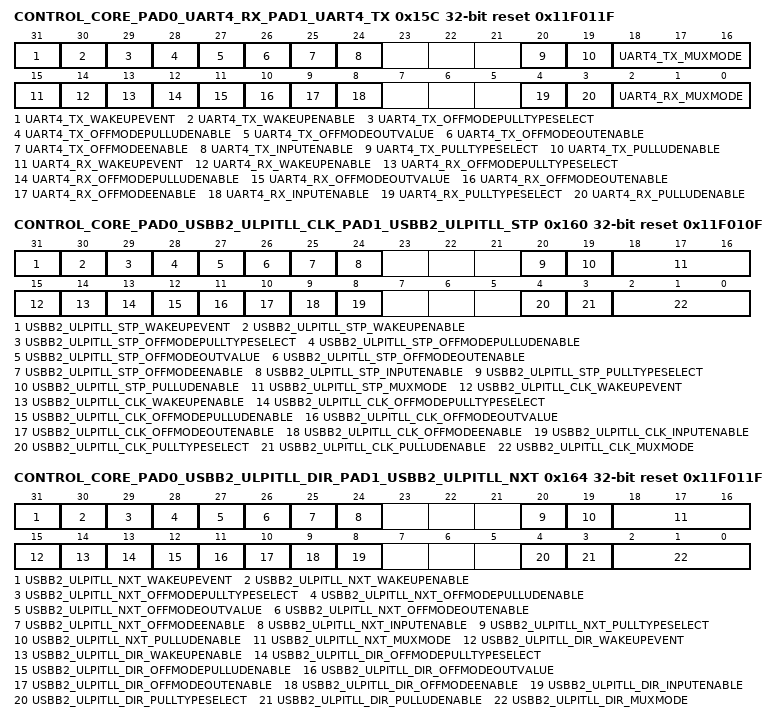
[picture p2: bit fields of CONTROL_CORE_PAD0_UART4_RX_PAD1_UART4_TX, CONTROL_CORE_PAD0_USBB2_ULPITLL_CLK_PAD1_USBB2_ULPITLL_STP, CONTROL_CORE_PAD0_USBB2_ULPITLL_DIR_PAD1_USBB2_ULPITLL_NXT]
0x15C CONTROL_CORE_PAD0_UART4_RX_PAD1_UART4_TX reset 0x11F011F — Register control for Pads uart4_rx and uart4_tx Access conditions. Read: unrestricted, Write: unrestricted
  [31] UART4_TX_WAKEUPEVENT ro — Pad_x wake-up event status latched in the IO
    0=UART4_TX_WAKEUPEVENT_0_r (No wake-up event occurred); 1=UART4_TX_WAKEUPEVENT_1_r (A wake-up event occurred)
  [30] UART4_TX_WAKEUPENABLE rw — Input pad wake-up enable (and OFF mode input enable value)
    values as CONTROL_CORE_PAD0_MCSPI1_CS2_PAD1_MCSPI1_CS3.MCSPI1_CS3_WAKEUPENABLE
  [29] UART4_TX_OFFMODEPULLTYPESELECT rw — OffMode mode pullup/down selection for pad uart4_tx
    0=Offmode pulldown selected; 1=Offmode pullup selected
  [28] UART4_TX_OFFMODEPULLUDENABLE rw — OffMode mode pullup/down enable for pad uart4_tx
    values as CONTROL_CORE_PAD0_MCSPI1_CS2_PAD1_MCSPI1_CS3.MCSPI1_CS3_OFFMODEPULLUDENABLE
  [27] UART4_TX_OFFMODEOUTVALUE rw — OffMode mode output value for pad uart4_tx
    0=Set value at 0; 1=Set value at 1
  [26] UART4_TX_OFFMODEOUTENABLE rw — OffMode mode output enable value for pad uart4_tx. This is an active low signal
    0=Output enable; 1=Output disable
  [25] UART4_TX_OFFMODEENABLE rw — OffMode mode override control for pad uart4_tx
    values as CONTROL_CORE_PAD0_MCSPI1_CS2_PAD1_MCSPI1_CS3.MCSPI1_CS3_OFFMODEENABLE
  [24] UART4_TX_INPUTENABLE rw — Input enable value for pad uart4_tx
    values as CONTROL_CORE_PAD0_MCSPI1_CS2_PAD1_MCSPI1_CS3.MCSPI1_CS3_INPUTENABLE
  [20] UART4_TX_PULLTYPESELECT rw — pullup/down selection for pad uart4_tx
    0=pulldown selected; 1=pullup selected
  [19] UART4_TX_PULLUDENABLE rw — pullup/down enable for pad uart4_tx
    0=pullup/down disabled; 1=pullup/down enabled
  [18:16] UART4_TX_MUXMODE rw — Functional multiplexing selection for pad uart4_tx
    0=Select uart4_tx; 1=Select sdmmc4_dat1; 2=Select kpd_col8; 3=Select gpio_156; 7=Select safe_mode
  [15] UART4_RX_WAKEUPEVENT ro — Pad_x wake-up event status latched in the IO
    0=UART4_RX_WAKEUPEVENT_0_r (No wake-up event occurred); 1=UART4_RX_WAKEUPEVENT_1_r (A wake-up event occurred)
  [14] UART4_RX_WAKEUPENABLE rw — Input pad wake-up enable (and OFF mode input enable value)
    values as CONTROL_CORE_PAD0_MCSPI1_CS2_PAD1_MCSPI1_CS3.MCSPI1_CS3_WAKEUPENABLE
  [13] UART4_RX_OFFMODEPULLTYPESELECT rw — OffMode mode pullup/down selection for pad uart4_rx
    0=Offmode pulldown selected; 1=Offmode pullup selected
  [12] UART4_RX_OFFMODEPULLUDENABLE rw — OffMode mode pullup/down enable for pad uart4_rx
    values as CONTROL_CORE_PAD0_MCSPI1_CS2_PAD1_MCSPI1_CS3.MCSPI1_CS3_OFFMODEPULLUDENABLE
  [11] UART4_RX_OFFMODEOUTVALUE rw — OffMode mode output value for pad uart4_rx
    0=Set value at 0; 1=Set value at 1
  [10] UART4_RX_OFFMODEOUTENABLE rw — OffMode mode output enable value for pad uart4_rx. This is an active low signal
    0=Output enable; 1=Output disable
  [9] UART4_RX_OFFMODEENABLE rw — OffMode mode override control for pad uart4_rx
    values as CONTROL_CORE_PAD0_MCSPI1_CS2_PAD1_MCSPI1_CS3.MCSPI1_CS3_OFFMODEENABLE
  [8] UART4_RX_INPUTENABLE rw — Input enable value for pad uart4_rx
    values as CONTROL_CORE_PAD0_MCSPI1_CS2_PAD1_MCSPI1_CS3.MCSPI1_CS3_INPUTENABLE
  [4] UART4_RX_PULLTYPESELECT rw — pullup/down selection for pad uart4_rx
    0=pulldown selected; 1=pullup selected
  [3] UART4_RX_PULLUDENABLE rw — pullup/down enable for pad uart4_rx
    0=pullup/down disabled; 1=pullup/down enabled
  [2:0] UART4_RX_MUXMODE rw — Functional multiplexing selection for pad uart4_rx
    0=Select uart4_rx; 1=Select sdmmc4_dat2; 2=Select kpd_row8; 3=Select gpio_155; 7=Select safe_mode
0x160 CONTROL_CORE_PAD0_USBB2_ULPITLL_CLK_PAD1_USBB2_ULPITLL_STP reset 0x11F010F — Register control for Pads usbb2_ulpitll_clk and usbb2_ulpitll_stp Access conditions. Read: unrestricted, Write: unrestricted
  [31] USBB2_ULPITLL_STP_WAKEUPEVENT ro — Pad_x wake-up event status latched in the IO
    0=USBB2_ULPITLL_STP_WAKEUPEVENT_0_r (No wake-up event occurred); 1=USBB2_ULPITLL_STP_WAKEUPEVENT_1_r (A wake-up event occurred)
  [30] USBB2_ULPITLL_STP_WAKEUPENABLE rw — Input pad wake-up enable (and OFF mode input enable value)
    values as CONTROL_CORE_PAD0_MCSPI1_CS2_PAD1_MCSPI1_CS3.MCSPI1_CS3_WAKEUPENABLE
  [29] USBB2_ULPITLL_STP_OFFMODEPULLTYPESELECT rw — OffMode mode pullup/down selection for pad usbb2_ulpitll_stp
    0=Offmode pulldown selected; 1=Offmode pullup selected
  [28] USBB2_ULPITLL_STP_OFFMODEPULLUDENABLE rw — OffMode mode pullup/down enable for pad usbb2_ulpitll_stp
    values as CONTROL_CORE_PAD0_MCSPI1_CS2_PAD1_MCSPI1_CS3.MCSPI1_CS3_OFFMODEPULLUDENABLE
  [27] USBB2_ULPITLL_STP_OFFMODEOUTVALUE rw — OffMode mode output value for pad usbb2_ulpitll_stp
    0=Set value at 0; 1=Set value at 1
  [26] USBB2_ULPITLL_STP_OFFMODEOUTENABLE rw — OffMode mode output enable value for pad usbb2_ulpitll_stp. This is an active low signal
    0=Output enable; 1=Output disable
  [25] USBB2_ULPITLL_STP_OFFMODEENABLE rw — OffMode mode override control for pad usbb2_ulpitll_stp
    values as CONTROL_CORE_PAD0_MCSPI1_CS2_PAD1_MCSPI1_CS3.MCSPI1_CS3_OFFMODEENABLE
  [24] USBB2_ULPITLL_STP_INPUTENABLE rw — Input enable value for pad usbb2_ulpitll_stp
    values as CONTROL_CORE_PAD0_MCSPI1_CS2_PAD1_MCSPI1_CS3.MCSPI1_CS3_INPUTENABLE
  [20] USBB2_ULPITLL_STP_PULLTYPESELECT rw — pullup/down selection for pad usbb2_ulpitll_stp
    0=pulldown selected; 1=pullup selected
  [19] USBB2_ULPITLL_STP_PULLUDENABLE rw — pullup/down enable for pad usbb2_ulpitll_stp
    0=pullup/down disabled; 1=pullup/down enabled
  [18:16] USBB2_ULPITLL_STP_MUXMODE rw — Functional multiplexing selection for pad usbb2_ulpitll_stp
    0=Select usbb2_ulpitll_stp; 1=Select usbb2_ulpiphy_stp; 2=Select sdmmc4_clk; 3=Select gpio_158; 4=Select hsi2_cadata; 5=Select dispc2_data23; 7=Select safe_mode
  [15] USBB2_ULPITLL_CLK_WAKEUPEVENT ro — Pad_x wake-up event status latched in the IO
    0=USBB2_ULPITLL_CLK_WAKEUPEVENT_0_r (No wake-up event occurred); 1=USBB2_ULPITLL_CLK_WAKEUPEVENT_1_r (A wake-up event occurred)
  [14] USBB2_ULPITLL_CLK_WAKEUPENABLE rw — Input pad wake-up enable (and OFF mode input enable value)
    values as CONTROL_CORE_PAD0_MCSPI1_CS2_PAD1_MCSPI1_CS3.MCSPI1_CS3_WAKEUPENABLE
  [13] USBB2_ULPITLL_CLK_OFFMODEPULLTYPESELECT rw — OffMode mode pullup/down selection for pad usbb2_ulpitll_clk
    0=Offmode pulldown selected; 1=Offmode pullup selected
  [12] USBB2_ULPITLL_CLK_OFFMODEPULLUDENABLE rw — OffMode mode pullup/down enable for pad usbb2_ulpitll_clk
    values as CONTROL_CORE_PAD0_MCSPI1_CS2_PAD1_MCSPI1_CS3.MCSPI1_CS3_OFFMODEPULLUDENABLE
  [11] USBB2_ULPITLL_CLK_OFFMODEOUTVALUE rw — OffMode mode output value for pad usbb2_ulpitll_clk
    0=Set value at 0; 1=Set value at 1
  [10] USBB2_ULPITLL_CLK_OFFMODEOUTENABLE rw — OffMode mode output enable value for pad usbb2_ulpitll_clk. This is an active low signal
    0=Output enable; 1=Output disable
  [9] USBB2_ULPITLL_CLK_OFFMODEENABLE rw — OffMode mode override control for pad usbb2_ulpitll_clk
    values as CONTROL_CORE_PAD0_MCSPI1_CS2_PAD1_MCSPI1_CS3.MCSPI1_CS3_OFFMODEENABLE
  [8] USBB2_ULPITLL_CLK_INPUTENABLE rw — Input enable value for pad usbb2_ulpitll_clk
    values as CONTROL_CORE_PAD0_MCSPI1_CS2_PAD1_MCSPI1_CS3.MCSPI1_CS3_INPUTENABLE
  [4] USBB2_ULPITLL_CLK_PULLTYPESELECT rw — pullup/down selection for pad usbb2_ulpitll_clk
    0=pulldown selected; 1=pullup selected
  [3] USBB2_ULPITLL_CLK_PULLUDENABLE rw — pullup/down enable for pad usbb2_ulpitll_clk
    0=pullup/down disabled; 1=pullup/down enabled
  [2:0] USBB2_ULPITLL_CLK_MUXMODE rw — Functional multiplexing selection for pad usbb2_ulpitll_clk
    0=Select usbb2_ulpitll_clk; 1=Select usbb2_ulpiphy_clk; 2=Select sdmmc4_cmd; 3=Select gpio_157; 4=Select hsi2_cawake; 7=Select safe_mode
0x164 CONTROL_CORE_PAD0_USBB2_ULPITLL_DIR_PAD1_USBB2_ULPITLL_NXT reset 0x11F011F — Register control for Pads usbb2_ulpitll_dir and usbb2_ulpitll_nxt Access conditions. Read: unrestricted, Write: unrestricted
  [31] USBB2_ULPITLL_NXT_WAKEUPEVENT ro — Pad_x wake-up event status latched in the IO
    0=USBB2_ULPITLL_NXT_WAKEUPEVENT_0_r (No wake-up event occurred); 1=USBB2_ULPITLL_NXT_WAKEUPEVENT_1_r (A wake-up event occurred)
  [30] USBB2_ULPITLL_NXT_WAKEUPENABLE rw — Input pad wake-up enable (and OFF mode input enable value)
    values as CONTROL_CORE_PAD0_MCSPI1_CS2_PAD1_MCSPI1_CS3.MCSPI1_CS3_WAKEUPENABLE
  [29] USBB2_ULPITLL_NXT_OFFMODEPULLTYPESELECT rw — OffMode mode pullup/down selection for pad usbb2_ulpitll_nxt
    0=Offmode pulldown selected; 1=Offmode pullup selected
  [28] USBB2_ULPITLL_NXT_OFFMODEPULLUDENABLE rw — OffMode mode pullup/down enable for pad usbb2_ulpitll_nxt
    values as CONTROL_CORE_PAD0_MCSPI1_CS2_PAD1_MCSPI1_CS3.MCSPI1_CS3_OFFMODEPULLUDENABLE
  [27] USBB2_ULPITLL_NXT_OFFMODEOUTVALUE rw — OffMode mode output value for pad usbb2_ulpitll_nxt
    0=Set value at 0; 1=Set value at 1
  [26] USBB2_ULPITLL_NXT_OFFMODEOUTENABLE rw — OffMode mode output enable value for pad usbb2_ulpitll_nxt. This is an active low signal
    0=Output enable; 1=Output disable
  [25] USBB2_ULPITLL_NXT_OFFMODEENABLE rw — OffMode mode override control for pad usbb2_ulpitll_nxt
    values as CONTROL_CORE_PAD0_MCSPI1_CS2_PAD1_MCSPI1_CS3.MCSPI1_CS3_OFFMODEENABLE
  [24] USBB2_ULPITLL_NXT_INPUTENABLE rw — Input enable value for pad usbb2_ulpitll_nxt
    values as CONTROL_CORE_PAD0_MCSPI1_CS2_PAD1_MCSPI1_CS3.MCSPI1_CS3_INPUTENABLE
  [20] USBB2_ULPITLL_NXT_PULLTYPESELECT rw — pullup/down selection for pad usbb2_ulpitll_nxt
    0=pulldown selected; 1=pullup selected
  [19] USBB2_ULPITLL_NXT_PULLUDENABLE rw — pullup/down enable for pad usbb2_ulpitll_nxt
    0=pullup/down disabled; 1=pullup/down enabled
  [18:16] USBB2_ULPITLL_NXT_MUXMODE rw — Functional multiplexing selection for pad usbb2_ulpitll_nxt
    0=Select usbb2_ulpitll_nxt; 1=Select usbb2_ulpiphy_nxt; 2=Select sdmmc4_dat1; 3=Select gpio_160; 4=Select hsi2_acready; 5=Select dispc2_data21; 7=Select safe_mode
  [15] USBB2_ULPITLL_DIR_WAKEUPEVENT ro — Pad_x wake-up event status latched in the IO
    0=USBB2_ULPITLL_DIR_WAKEUPEVENT_0_r (No wake-up event occurred); 1=USBB2_ULPITLL_DIR_WAKEUPEVENT_1_r (A wake-up event occurred)
  [14] USBB2_ULPITLL_DIR_WAKEUPENABLE rw — Input pad wake-up enable (and OFF mode input enable value)
    values as CONTROL_CORE_PAD0_MCSPI1_CS2_PAD1_MCSPI1_CS3.MCSPI1_CS3_WAKEUPENABLE
  [13] USBB2_ULPITLL_DIR_OFFMODEPULLTYPESELECT rw — OffMode mode pullup/down selection for pad usbb2_ulpitll_dir
    0=Offmode pulldown selected; 1=Offmode pullup selected
  [12] USBB2_ULPITLL_DIR_OFFMODEPULLUDENABLE rw — OffMode mode pullup/down enable for pad usbb2_ulpitll_dir
    values as CONTROL_CORE_PAD0_MCSPI1_CS2_PAD1_MCSPI1_CS3.MCSPI1_CS3_OFFMODEPULLUDENABLE
  [11] USBB2_ULPITLL_DIR_OFFMODEOUTVALUE rw — OffMode mode output value for pad usbb2_ulpitll_dir
    0=Set value at 0; 1=Set value at 1
  [10] USBB2_ULPITLL_DIR_OFFMODEOUTENABLE rw — OffMode mode output enable value for pad usbb2_ulpitll_dir. This is an active low signal
    0=Output enable; 1=Output disable
  [9] USBB2_ULPITLL_DIR_OFFMODEENABLE rw — OffMode mode override control for pad usbb2_ulpitll_dir
    values as CONTROL_CORE_PAD0_MCSPI1_CS2_PAD1_MCSPI1_CS3.MCSPI1_CS3_OFFMODEENABLE
  [8] USBB2_ULPITLL_DIR_INPUTENABLE rw — Input enable value for pad usbb2_ulpitll_dir
    values as CONTROL_CORE_PAD0_MCSPI1_CS2_PAD1_MCSPI1_CS3.MCSPI1_CS3_INPUTENABLE
  [4] USBB2_ULPITLL_DIR_PULLTYPESELECT rw — pullup/down selection for pad usbb2_ulpitll_dir
    0=pulldown selected; 1=pullup selected
  [3] USBB2_ULPITLL_DIR_PULLUDENABLE rw — pullup/down enable for pad usbb2_ulpitll_dir
    0=pullup/down disabled; 1=pullup/down enabled
  [2:0] USBB2_ULPITLL_DIR_MUXMODE rw — Functional multiplexing selection for pad usbb2_ulpitll_dir
    0=Select usbb2_ulpitll_dir; 1=Select usbb2_ulpiphy_dir; 2=Select sdmmc4_dat0; 3=Select gpio_159; 4=Select hsi2_caflag; 5=Select dispc2_data22; 7=Select safe_mode
